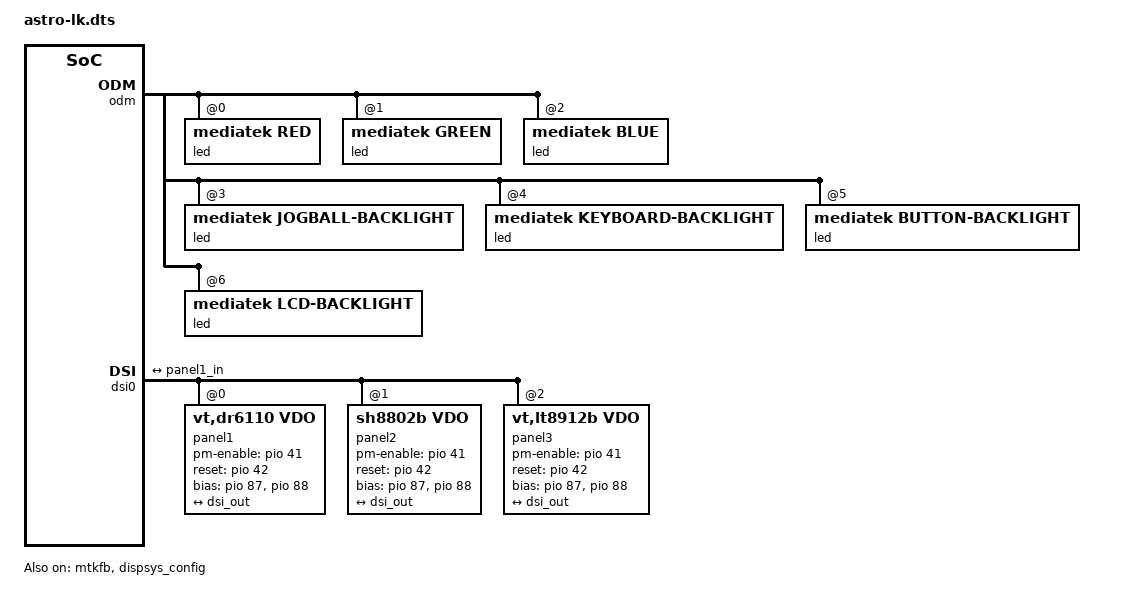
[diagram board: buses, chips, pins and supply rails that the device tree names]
// SPDX-License-Identifier: GPL-2.0-only
/*
 * LK board-config overlay for the Astro's `dtbo_a` partition.
 *
 * LK applies `dtbo` twice per boot (display test 1, 2026-11-25,
 * docs/session-log.md): at ~350 ms onto its own copy of the stock base
 * DTB (lk_main_dtb, 171401 bytes), where its display, LED and GPIO code
 * read it, and at ~3 s onto the kernel DTB in boot_a ("boot image
 * dtb_overlay"), where a failure is fatal (boot_info.c:61 img_loaded).
 *
 * - The no-op overlay passes on our DTB but leaves LK without its board
 *   config: no panel reset/backlight, black screen.
 * - The stock overlay (293 fragments) feeds LK but cannot resolve its
 *   labels in our DTB ("Couldn't find 'reserved_memory' symbol").
 *
 * This overlay carries only the stock fragments LK's display path needs,
 * copied from the stock dtbo_a, all on labels that exist in both DTBs:
 *   stock fragment@2  -> &odm            led@0-6 (led@6 = LCM backlight)
 *   stock fragment@3  -> &pio            LCM reset / TE pinctrl states
 *   stock fragment@9  -> &mtkfb          LCM pinctrl list
 *   stock fragment@10 -> &dispsys_config LCM pinctrl list
 *   stock fragment@11 -> &dsi0           panel1/2/3 + endpoints
 *   stock fragment@50 -> &gpio           gpio_init_default (vendor DWS)
 * Left out of fragment@2: vibrator@0 and usb_c_pinctrl (they reference
 * pinctrl states of stock fragments not carried here).
 *
 * In our kernel DTB these labels resolve into the inert /lk-sink
 * container (bin/build-boot-img.sh points __symbols__ there), so nothing
 * lands on a real mainline node.
 *
 * gpio_init_default rows: <pin mode dir dout pullen pullsel smt?>
 * (7 cells per pin, as stock).
 */
/dts-v1/;
/plugin/;

&odm {
	led@0 {
		compatible = "mediatek,red";
		led_mode = <0>;
		data = <1>;
		pwm_config = <0 0 0 0 0>;
	};

	led@1 {
		compatible = "mediatek,green";
		led_mode = <0>;
		data = <1>;
		pwm_config = <0 0 0 0 0>;
	};

	led@2 {
		compatible = "mediatek,blue";
		led_mode = <0>;
		data = <1>;
		pwm_config = <0 0 0 0 0>;
	};

	led@3 {
		compatible = "mediatek,jogball-backlight";
		led_mode = <0>;
		data = <1>;
		pwm_config = <0 0 0 0 0>;
	};

	led@4 {
		compatible = "mediatek,keyboard-backlight";
		led_mode = <0>;
		data = <1>;
		pwm_config = <0 0 0 0 0>;
	};

	led@5 {
		compatible = "mediatek,button-backlight";
		led_mode = <0>;
		data = <1>;
		pwm_config = <0 0 0 0 0>;
	};

	led@6 {
		compatible = "mediatek,lcd-backlight";
		led_mode = <4>;
		data = <1>;
		pwm_config = <0 1 0 0 0>;
	};
};

&pio {
	lcd_bias_enp1: lcd_bias_enp1_gpio {
	};

	lcd_bias_enp0: lcd_bias_enp0_gpio {
	};

	lcd_bias_enn1: lcd_bias_enn1_gpio {
	};

	lcd_bias_enn0: lcd_bias_enn0_gpio {
	};

	/* GPIO42 (0x2a00 = pin 42, function 0): panel reset */
	lcm_rst_out1: lcm_rst_out1_gpio {
		pins_cmd_dat {
			pinmux = <0x2a00>;
			slew-rate = <1>;
			output-high;
		};
	};

	lcm_rst_out0: lcm_rst_out0_gpio {
		pins_cmd_dat {
			pinmux = <0x2a00>;
			slew-rate = <1>;
			output-low;
		};
	};

	/* GPIO41 function 1 (0x2901): DSI TE */
	lcm_dsi_te: lcm_dsi_te {
		pins_cmd_dat {
			pinmux = <0x2901>;
		};
	};
};

&mtkfb {
	pinctrl-names = "lcd_bias_enp1_gpio", "lcd_bias_enp0_gpio",
			"lcd_bias_enn1_gpio", "lcd_bias_enn0_gpio",
			"lcm_rst_out1_gpio", "lcm_rst_out0_gpio", "mode_te_te";
	pinctrl-0 = <&lcd_bias_enp1>;
	pinctrl-1 = <&lcd_bias_enp0>;
	pinctrl-2 = <&lcd_bias_enn1>;
	pinctrl-3 = <&lcd_bias_enn0>;
	pinctrl-4 = <&lcm_rst_out1>;
	pinctrl-5 = <&lcm_rst_out0>;
	pinctrl-6 = <&lcm_dsi_te>;
	status = "okay";
};

&dispsys_config {
	pinctrl-names = "lcm_rst_out1_gpio", "lcm_rst_out0_gpio", "mode_te_te";
	pinctrl-0 = <&lcm_rst_out1>;
	pinctrl-1 = <&lcm_rst_out0>;
	pinctrl-2 = <&lcm_dsi_te>;
	status = "okay";
};

&dsi0 {
	status = "okay";
	#address-cells = <1>;
	#size-cells = <0>;

	panel1@0 {
		compatible = "vt,dr6110,vdo";
		reg = <0>;
		pm-enable-gpios = <&pio 41 0>;
		reset-gpios = <&pio 42 0>;
		bias-gpios = <&pio 87 0>, <&pio 88 0>;
		pinctrl-names = "default";

		port {
			panel1_in: endpoint {
				remote-endpoint = <&dsi_out>;
			};
		};
	};

	panel2@0 {
		compatible = "sh8802b,vdo";
		reg = <1>;
		pm-enable-gpios = <&pio 41 0>;
		reset-gpios = <&pio 42 0>;
		bias-gpios = <&pio 87 0>, <&pio 88 0>;
		pinctrl-names = "default";

		port {
			panel2_in: endpoint {
				remote-endpoint = <&dsi_out>;
			};
		};
	};

	panel3@0 {
		compatible = "vt,lt8912b,vdo";
		reg = <2>;
		pm-enable-gpios = <&pio 41 0>;
		reset-gpios = <&pio 42 0>;
		bias-gpios = <&pio 87 0>, <&pio 88 0>;
		pinctrl-names = "default";

		port {
			panel3_in: endpoint {
				remote-endpoint = <&dsi_out>;
			};
		};
	};

	ports {
		port {
			dsi_out: endpoint {
				remote-endpoint = <&panel1_in>;
			};
		};
	};
};

&gpio {
	gpio_init_default =
			<0x00 0x00 0x00 0x00 0x01 0x01 0x01>,
			<0x01 0x00 0x00 0x00 0x01 0x01 0x01>,
			<0x02 0x00 0x00 0x00 0x01 0x01 0x01>,
			<0x03 0x00 0x00 0x00 0x01 0x00 0x01>,
			<0x04 0x00 0x00 0x00 0x01 0x01 0x01>,
			<0x05 0x00 0x01 0x00 0x01 0x00 0x01>,
			<0x06 0x00 0x01 0x00 0x01 0x00 0x01>,
			<0x07 0x00 0x00 0x00 0x01 0x01 0x01>,
			<0x08 0x00 0x01 0x00 0x01 0x00 0x01>,
			<0x09 0x00 0x01 0x00 0x01 0x00 0x01>,
			<0x0a 0x00 0x01 0x01 0x01 0x00 0x00>,
			<0x0b 0x00 0x00 0x00 0x01 0x00 0x00>,
			<0x0c 0x00 0x01 0x00 0x01 0x00 0x00>,
			<0x0d 0x00 0x01 0x00 0x01 0x00 0x00>,
			<0x0e 0x00 0x01 0x00 0x01 0x00 0x00>,
			<0x0f 0x00 0x00 0x00 0x01 0x00 0x00>,
			<0x10 0x00 0x00 0x00 0x01 0x01 0x01>,
			<0x11 0x00 0x00 0x00 0x01 0x01 0x01>,
			<0x12 0x00 0x01 0x00 0x01 0x00 0x01>,
			<0x13 0x00 0x00 0x00 0x01 0x00 0x01>,
			<0x14 0x00 0x01 0x00 0x01 0x00 0x01>,
			<0x15 0x00 0x00 0x00 0x01 0x01 0x01>,
			<0x16 0x00 0x00 0x00 0x01 0x00 0x01>,
			<0x17 0x00 0x00 0x00 0x01 0x01 0x01>,
			<0x18 0x00 0x00 0x00 0x01 0x01 0x01>,
			<0x19 0x00 0x00 0x00 0x01 0x01 0x01>,
			<0x1a 0x00 0x01 0x00 0x01 0x00 0x01>,
			<0x1b 0x00 0x01 0x01 0x01 0x00 0x01>,
			<0x1c 0x01 0x00 0x00 0x01 0x00 0x01>,
			<0x1d 0x00 0x01 0x00 0x01 0x00 0x01>,
			<0x1e 0x00 0x01 0x00 0x01 0x00 0x01>,
			<0x1f 0x01 0x00 0x00 0x00 0x00 0x01>,
			<0x20 0x01 0x00 0x00 0x00 0x00 0x01>,
			<0x21 0x01 0x00 0x00 0x00 0x00 0x01>,
			<0x22 0x00 0x01 0x00 0x01 0x00 0x01>,
			<0x23 0x01 0x00 0x00 0x01 0x00 0x01>,
			<0x24 0x01 0x00 0x00 0x01 0x00 0x00>,
			<0x25 0x01 0x00 0x00 0x01 0x00 0x00>,
			<0x26 0x00 0x00 0x00 0x01 0x00 0x00>,
			<0x27 0x01 0x00 0x00 0x01 0x00 0x00>,
			<0x28 0x01 0x00 0x00 0x00 0x00 0x01>,
			<0x29 0x01 0x00 0x00 0x01 0x00 0x01>,
			<0x2a 0x01 0x00 0x00 0x00 0x00 0x00>,
			<0x2b 0x01 0x00 0x00 0x01 0x01 0x01>,
			<0x2c 0x01 0x00 0x00 0x01 0x01 0x01>,
			<0x2d 0x01 0x00 0x00 0x00 0x00 0x01>,
			<0x2e 0x01 0x00 0x00 0x00 0x00 0x01>,
			<0x2f 0x01 0x00 0x00 0x01 0x01 0x01>,
			<0x30 0x01 0x00 0x00 0x01 0x01 0x01>,
			<0x31 0x01 0x00 0x00 0x00 0x00 0x01>,
			<0x32 0x01 0x00 0x00 0x00 0x00 0x01>,
			<0x33 0x01 0x00 0x00 0x00 0x00 0x01>,
			<0x34 0x01 0x00 0x00 0x01 0x01 0x01>,
			<0x35 0x01 0x00 0x00 0x01 0x01 0x01>,
			<0x36 0x01 0x00 0x00 0x01 0x01 0x01>,
			<0x37 0x01 0x00 0x00 0x01 0x01 0x01>,
			<0x38 0x01 0x00 0x00 0x01 0x01 0x01>,
			<0x39 0x01 0x00 0x00 0x00 0x00 0x00>,
			<0x3a 0x01 0x00 0x00 0x01 0x00 0x00>,
			<0x3b 0x01 0x00 0x00 0x01 0x00 0x01>,
			<0x3c 0x01 0x00 0x00 0x01 0x00 0x01>,
			<0x3d 0x01 0x00 0x00 0x01 0x00 0x01>,
			<0x3e 0x01 0x00 0x00 0x01 0x00 0x01>,
			<0x3f 0x00 0x00 0x00 0x01 0x00 0x00>,
			<0x40 0x00 0x00 0x00 0x01 0x00 0x00>,
			<0x41 0x01 0x00 0x00 0x00 0x00 0x00>,
			<0x42 0x00 0x01 0x01 0x01 0x00 0x00>,
			<0x43 0x01 0x00 0x00 0x00 0x00 0x00>,
			<0x44 0x01 0x00 0x00 0x00 0x00 0x00>,
			<0x45 0x01 0x00 0x00 0x00 0x00 0x00>,
			<0x46 0x01 0x00 0x00 0x00 0x00 0x00>,
			<0x47 0x01 0x00 0x00 0x00 0x00 0x00>,
			<0x48 0x01 0x00 0x00 0x00 0x00 0x00>,
			<0x49 0x01 0x00 0x00 0x00 0x00 0x00>,
			<0x4a 0x01 0x00 0x00 0x00 0x00 0x00>,
			<0x4b 0x01 0x00 0x00 0x00 0x00 0x00>,
			<0x4c 0x01 0x00 0x00 0x00 0x00 0x00>,
			<0x4d 0x01 0x00 0x00 0x00 0x00 0x00>,
			<0x4e 0x01 0x00 0x00 0x00 0x00 0x00>,
			<0x4f 0x01 0x00 0x00 0x00 0x00 0x00>,
			<0x50 0x01 0x00 0x00 0x00 0x00 0x00>,
			<0x51 0x01 0x00 0x00 0x00 0x00 0x00>,
			<0x52 0x01 0x00 0x00 0x00 0x00 0x00>,
			<0x53 0x01 0x00 0x00 0x00 0x00 0x00>,
			<0x54 0x01 0x00 0x00 0x00 0x00 0x00>,
			<0x55 0x01 0x00 0x00 0x00 0x00 0x00>,
			<0x56 0x01 0x00 0x00 0x01 0x00 0x00>,
			<0x57 0x01 0x00 0x00 0x00 0x00 0x00>,
			<0x58 0x01 0x00 0x00 0x01 0x00 0x00>,
			<0x59 0x01 0x00 0x00 0x00 0x00 0x01>,
			<0x5a 0x01 0x00 0x00 0x00 0x00 0x01>,
			<0x5c 0x01 0x00 0x00 0x01 0x01 0x00>,
			<0x5d 0x01 0x00 0x00 0x00 0x00 0x00>,
			<0x5e 0x00 0x00 0x00 0x01 0x01 0x00>,
			<0x5f 0x00 0x00 0x00 0x01 0x01 0x00>,
			<0x60 0x00 0x01 0x00 0x01 0x00 0x00>,
			<0x61 0x00 0x01 0x00 0x01 0x00 0x00>,
			<0x62 0x00 0x00 0x00 0x01 0x00 0x00>,
			<0x63 0x00 0x01 0x00 0x01 0x00 0x00>,
			<0x64 0x00 0x00 0x00 0x01 0x00 0x00>,
			<0x65 0x00 0x00 0x00 0x01 0x00 0x00>,
			<0x66 0x00 0x00 0x00 0x01 0x00 0x00>,
			<0x67 0x00 0x00 0x00 0x01 0x00 0x00>,
			<0x68 0x00 0x00 0x00 0x01 0x00 0x00>,
			<0x69 0x00 0x00 0x00 0x01 0x00 0x00>,
			<0x6a 0x00 0x00 0x00 0x01 0x00 0x00>,
			<0x6b 0x00 0x01 0x00 0x01 0x00 0x00>,
			<0x6c 0x00 0x01 0x00 0x01 0x00 0x00>,
			<0x6d 0x00 0x00 0x00 0x01 0x00 0x00>,
			<0x6e 0x00 0x00 0x00 0x01 0x00 0x00>,
			<0x6f 0x00 0x00 0x00 0x01 0x00 0x00>,
			<0x70 0x00 0x00 0x00 0x01 0x00 0x00>,
			<0x71 0x00 0x00 0x00 0x01 0x00 0x00>,
			<0x72 0x02 0x00 0x00 0x01 0x00 0x00>,
			<0x73 0x02 0x00 0x00 0x00 0x00 0x00>,
			<0x74 0x02 0x00 0x00 0x00 0x00 0x00>,
			<0x75 0x02 0x00 0x00 0x00 0x00 0x00>,
			<0x76 0x02 0x00 0x00 0x01 0x01 0x01>,
			<0x77 0x02 0x00 0x00 0x01 0x01 0x01>,
			<0x78 0x01 0x00 0x00 0x01 0x01 0x01>,
			<0x79 0x01 0x00 0x00 0x01 0x01 0x01>,
			<0x7a 0x01 0x00 0x00 0x01 0x01 0x01>,
			<0x7b 0x01 0x00 0x00 0x01 0x01 0x01>,
			<0x7c 0x01 0x00 0x00 0x01 0x01 0x01>,
			<0x7d 0x01 0x00 0x00 0x01 0x01 0x01>,
			<0x7e 0x00 0x01 0x00 0x01 0x00 0x00>,
			<0x7f 0x00 0x01 0x00 0x01 0x00 0x00>,
			<0x80 0x00 0x01 0x00 0x01 0x00 0x00>,
			<0x81 0x00 0x01 0x00 0x01 0x00 0x00>,
			<0x82 0x00 0x01 0x00 0x01 0x00 0x00>,
			<0x83 0x00 0x01 0x00 0x01 0x00 0x00>,
			<0x84 0x00 0x01 0x00 0x01 0x00 0x00>,
			<0x85 0x00 0x01 0x00 0x01 0x00 0x00>,
			<0x86 0x00 0x01 0x00 0x01 0x00 0x00>,
			<0x87 0x00 0x01 0x00 0x01 0x00 0x00>,
			<0x88 0x01 0x00 0x00 0x00 0x00 0x00>,
			<0x89 0x00 0x01 0x00 0x01 0x00 0x00>,
			<0x8a 0x00 0x01 0x00 0x01 0x00 0x00>,
			<0x8b 0x01 0x00 0x00 0x01 0x01 0x01>,
			<0x8c 0x01 0x00 0x00 0x01 0x01 0x01>,
			<0x8d 0x01 0x00 0x00 0x01 0x01 0x01>,
			<0x8e 0x01 0x00 0x00 0x01 0x01 0x01>,
			<0x8f 0x00 0x01 0x00 0x01 0x00 0x00>,
			<0x90 0x00 0x01 0x00 0x01 0x00 0x00>,
			<0x91 0x00 0x01 0x00 0x01 0x00 0x00>,
			<0x92 0x00 0x01 0x00 0x01 0x00 0x00>,
			<0x93 0x00 0x01 0x00 0x01 0x00 0x00>,
			<0x94 0x00 0x01 0x01 0x01 0x00 0x00>,
			<0x95 0x01 0x00 0x00 0x00 0x00 0x00>,
			<0x96 0x01 0x00 0x00 0x00 0x00 0x00>,
			<0x97 0x01 0x00 0x00 0x00 0x00 0x00>,
			<0x98 0x00 0x00 0x00 0x01 0x00 0x00>,
			<0x99 0x01 0x00 0x00 0x01 0x00 0x00>,
			<0x9a 0x01 0x00 0x00 0x01 0x01 0x00>,
			<0x9b 0x01 0x00 0x00 0x01 0x01 0x00>,
			<0x9c 0x01 0x00 0x00 0x00 0x00 0x00>,
			<0x9d 0x01 0x00 0x00 0x00 0x00 0x00>,
			<0x9e 0x01 0x00 0x00 0x01 0x00 0x00>,
			<0x9f 0x01 0x00 0x00 0x00 0x00 0x00>,
			<0xa0 0x01 0x00 0x00 0x01 0x01 0x01>,
			<0xa1 0x01 0x00 0x00 0x01 0x01 0x01>,
			<0xa2 0x00 0x00 0x00 0x01 0x00 0x00>,
			<0xa3 0x00 0x00 0x00 0x01 0x00 0x00>,
			<0xa4 0x00 0x00 0x00 0x01 0x00 0x00>,
			<0xa5 0x01 0x00 0x00 0x01 0x00 0x00>,
			<0xa6 0x01 0x00 0x00 0x01 0x00 0x00>,
			<0xa7 0x00 0x00 0x00 0x01 0x00 0x00>,
			<0xa8 0x06 0x00 0x00 0x01 0x00 0x00>,
			<0xa9 0x06 0x00 0x00 0x01 0x00 0x00>,
			<0xaa 0x00 0x01 0x00 0x01 0x00 0x00>,
			<0xab 0x00 0x01 0x00 0x01 0x00 0x00>,
			<0xac 0x00 0x00 0x00 0x01 0x00 0x00>,
			<0xad 0x00 0x00 0x00 0x01 0x00 0x00>,
			<0xae 0x00 0x00 0x00 0x01 0x00 0x00>,
			<0xaf 0x00 0x00 0x00 0x01 0x00 0x00>,
			<0xb0 0x00 0x00 0x00 0x01 0x00 0x00>,
			<0xb1 0x00 0x00 0x00 0x01 0x00 0x00>,
			<0xb2 0x00 0x00 0x00 0x01 0x00 0x00>,
			<0xb3 0x00 0x00 0x00 0x01 0x00 0x00>,
			<0xb4 0x00 0x00 0x00 0x01 0x00 0x00>,
			<0xb5 0x00 0x00 0x00 0x01 0x00 0x00>,
			<0xb6 0x00 0x00 0x00 0x01 0x00 0x00>,
			<0xc3 0x01 0x00 0x00 0x00 0x00 0x01>,
			<0xc4 0x01 0x00 0x00 0x00 0x00 0x01>,
			<0xc5 0x01 0x00 0x00 0x00 0x00 0x01>,
			<0xc6 0x01 0x00 0x00 0x00 0x00 0x01>,
			<0xc7 0x01 0x00 0x00 0x01 0x00 0x01>,
			<0xc8 0x01 0x00 0x00 0x01 0x01 0x01>,
			<0xc9 0x01 0x00 0x00 0x01 0x01 0x01>,
			<0xca 0x01 0x00 0x00 0x01 0x01 0x01>,
			<0xcb 0x01 0x00 0x00 0x01 0x01 0x01>,
			<0xcc 0x01 0x00 0x00 0x01 0x01 0x01>,
			<0xcd 0x01 0x00 0x00 0x01 0x01 0x01>,
			<0xce 0x01 0x00 0x00 0x00 0x00 0x01>,
			<0xcf 0x01 0x00 0x00 0x00 0x00 0x01>,
			<0xd0 0x01 0x00 0x00 0x00 0x00 0x00>,
			<0xd1 0x01 0x00 0x00 0x01 0x00 0x00>,
			<0xd2 0x01 0x00 0x00 0x00 0x00 0x00>,
			<0xd3 0x01 0x00 0x00 0x01 0x00 0x00>,
			<0xd4 0x01 0x00 0x00 0x00 0x00 0x00>,
			<0xd5 0x01 0x00 0x00 0x01 0x00 0x01>,
			<0xd6 0x01 0x00 0x00 0x00 0x00 0x01>,
			<0xd7 0x01 0x00 0x00 0x00 0x00 0x01>,
			<0xd8 0x01 0x00 0x00 0x00 0x00 0x01>,
			<0xd9 0x01 0x00 0x00 0x00 0x00 0x01>,
			<0xda 0x01 0x00 0x00 0x01 0x00 0x01>,
			<0xdb 0x01 0x00 0x00 0x01 0x00 0x01>,
			<0xdc 0x00 0x00 0x00 0x01 0x00 0x00>,
			<0xdd 0x00 0x00 0x00 0x01 0x00 0x00>,
			<0xde 0x00 0x00 0x00 0x01 0x00 0x00>,
			<0xdf 0x00 0x00 0x00 0x01 0x00 0x00>,
			<0xe0 0x00 0x00 0x00 0x01 0x00 0x00>,
			<0xe1 0x00 0x00 0x00 0x01 0x00 0x00>,
			<0xe2 0x00 0x00 0x00 0x01 0x00 0x00>,
			<0xe3 0x00 0x00 0x00 0x01 0x00 0x00>;
};
